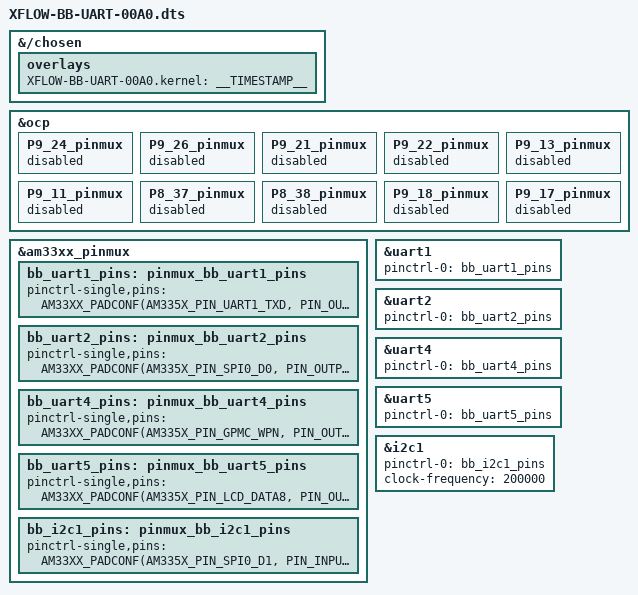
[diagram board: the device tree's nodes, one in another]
// SPDX-License-Identifier: GPL-2.0-only
/*
 * Virtual cape for UART1, 2, 4, 5 on connector pins P9.24 P9.26 P9.21 P9.22 P9.13 P9.11 P9.37 P9.38
 */

/dts-v1/;
/plugin/;

#include <dt-bindings/pinctrl/am33xx.h>
#include <dt-bindings/gpio/gpio.h>

/*
 * Helper to show loaded overlays under: /proc/device-tree/chosen/overlays/
 */
&{/chosen} {
	overlays {
		XFLOW-BB-UART-00A0.kernel = __TIMESTAMP__;
	};
};

/*
 * Free up the pins used by the cape from the pinmux helpers.
 */
&ocp {
	P9_24_pinmux { status = "disabled"; };	/* P9_24 uart1_txd */
	P9_26_pinmux { status = "disabled"; };	/* P9_26 uart1_rxd */
	P9_21_pinmux { status = "disabled"; };	/* P9_21 spi0_d0.uart2_txd */
	P9_22_pinmux { status = "disabled"; };	/* P9_22 spi0_sclk.uart2_rxd */
	P9_13_pinmux { status = "disabled"; };	/* P9_13 uart4_txd */
	P9_11_pinmux { status = "disabled"; };	/* P9_11 uart4_rxd */
	P8_37_pinmux { status = "disabled"; };	/* P8_37 lcd_data8.uart5_txd */
	P8_38_pinmux { status = "disabled"; };	/* P8_38 lcd_data9.uart5_rxd */

    P9_18_pinmux { status = "disabled"; };	/* P9_18 spi0_d1.i2c1_sda */
	P9_17_pinmux { status = "disabled"; };	/* P9_17 spi0_cs0.i2c1_scl */
};

&am33xx_pinmux {
	bb_uart1_pins: pinmux_bb_uart1_pins {
		pinctrl-single,pins = <
			AM33XX_PADCONF(AM335X_PIN_UART1_TXD, PIN_OUTPUT, MUX_MODE0)	/* P9_24 uart1_txd.uart1_txd */
			AM33XX_PADCONF(AM335X_PIN_UART1_RXD, PIN_INPUT, MUX_MODE0)	/* P9_26 uart1_rxd.uart1_rxd */
		>;
	};

    bb_uart2_pins: pinmux_bb_uart2_pins {
		pinctrl-single,pins = <
			AM33XX_PADCONF(AM335X_PIN_SPI0_D0, PIN_OUTPUT, MUX_MODE1)	/* P9_21 spi0_d0.uart2_txd */
			AM33XX_PADCONF(AM335X_PIN_SPI0_SCLK, PIN_INPUT, MUX_MODE1)	/* P9_22 spi0_sclk.uart2_rxd */
		>;
	};

    bb_uart4_pins: pinmux_bb_uart4_pins {
		pinctrl-single,pins = <
			AM33XX_PADCONF(AM335X_PIN_GPMC_WPN, PIN_OUTPUT, MUX_MODE6)	/* P9_13 gpmc_wpn.uart4_txd_mux2 */
			AM33XX_PADCONF(AM335X_PIN_GPMC_WAIT0, PIN_INPUT, MUX_MODE6)	/* P9_11 gpmc_wait0.uart4_rxd_mux2 */
		>;
	};

    bb_uart5_pins: pinmux_bb_uart5_pins {
		pinctrl-single,pins = <
			AM33XX_PADCONF(AM335X_PIN_LCD_DATA8, PIN_OUTPUT, MUX_MODE4)	/* P8_37 lcd_data8.uart5_txd */
			AM33XX_PADCONF(AM335X_PIN_LCD_DATA9, PIN_INPUT, MUX_MODE4)	/* P8_38 lcd_data9.uart5_rxd */
		>;
	};

    bb_i2c1_pins: pinmux_bb_i2c1_pins {
		pinctrl-single,pins = <
			AM33XX_PADCONF(AM335X_PIN_SPI0_D1, PIN_INPUT_PULLUP | SLEWCTRL_SLOW | MUX_MODE2) /* spi0_d1.i2c1_sda */
			AM33XX_PADCONF(AM335X_PIN_SPI0_CS0, PIN_INPUT_PULLUP | SLEWCTRL_SLOW | MUX_MODE2) /* spi0_cs0.i2c1_scl */
		>;
	};

};

&uart1 {
	/* sudo agetty 115200 ttyS1 */
	status = "okay";
	pinctrl-names = "default";
	pinctrl-0 = <&bb_uart1_pins>;
};

&uart2 {
	/* sudo agetty 115200 ttyS2 */
	status = "okay";
	pinctrl-names = "default";
	pinctrl-0 = <&bb_uart2_pins>;
};

&uart4 {
	/* sudo agetty 115200 ttyS4 */
	status = "okay";
	pinctrl-names = "default";
	pinctrl-0 = <&bb_uart4_pins>;
};

&uart5 {
	/* sudo agetty 115200 ttyS5 */
	status = "okay";
	pinctrl-names = "default";
	pinctrl-0 = <&bb_uart5_pins>;
};

&i2c1 {
	status = "okay";
	pinctrl-names = "default";
	pinctrl-0 = <&bb_i2c1_pins>;

	clock-frequency = <200000>;

	#address-cells = <1>;
	#size-cells = <0>;

};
